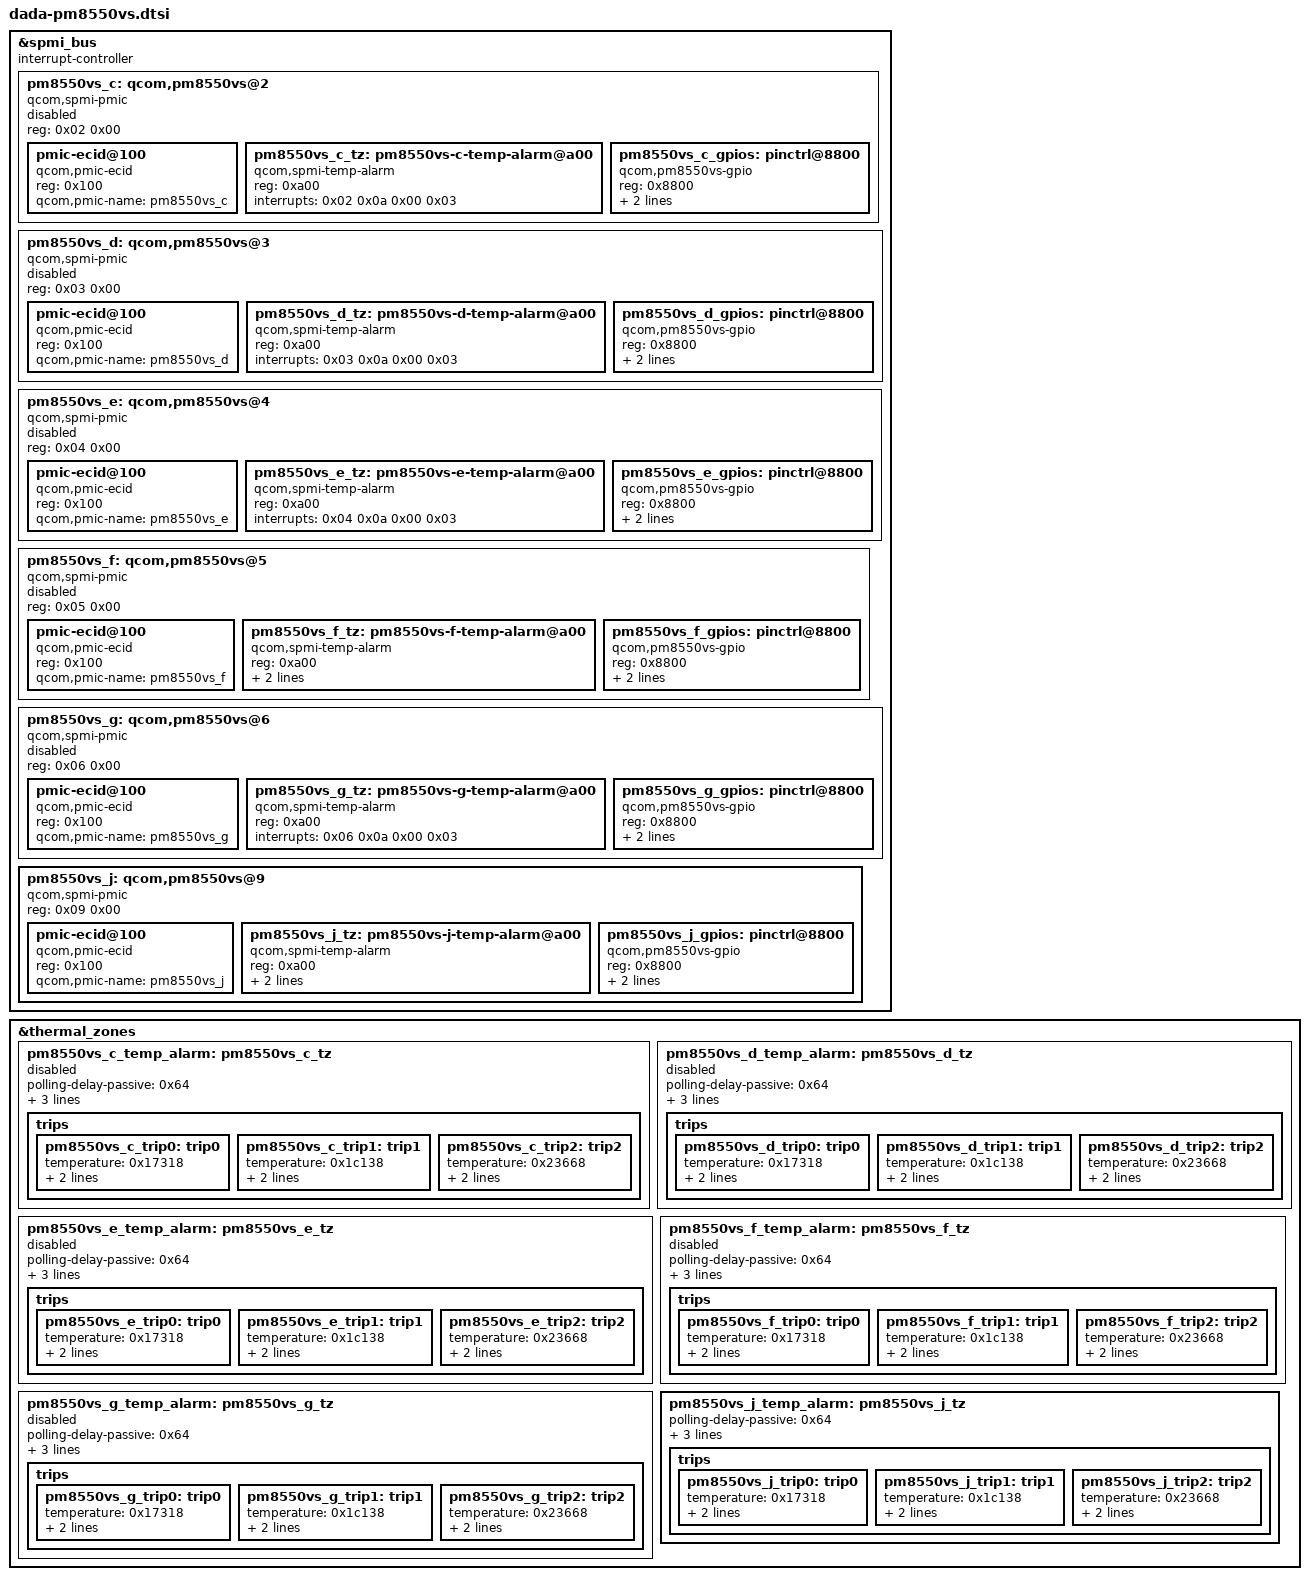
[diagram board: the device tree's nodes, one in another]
// SPDX-License-Identifier: BSD-3-Clause
/*
 * Copyright (c) 2023-2024 Qualcomm Innovation Center, Inc. All rights reserved.
 * Copyright (c) 2025 The LineageOS Project
 */

&spmi_bus {
	#address-cells = <0x02>;
	#size-cells = <0x00>;
	interrupt-controller;
	#interrupt-cells = <0x04>;

	pm8550vs_c: qcom,pm8550vs@2 {
		compatible = "qcom,spmi-pmic";
		reg = <0x02 0x00>;
		#address-cells = <0x01>;
		#size-cells = <0x00>;
		status = "disabled";

		pmic-ecid@100 {
			compatible = "qcom,pmic-ecid";
			reg = <0x100>;
			qcom,pmic-name = "pm8550vs_c";
		};

		pm8550vs_c_tz: pm8550vs-c-temp-alarm@a00 {
			compatible = "qcom,spmi-temp-alarm";
			reg = <0xa00>;
			interrupts = <0x02 0x0a 0x00 0x03>;
			#thermal-sensor-cells = <0x00>;
		};

		pm8550vs_c_gpios: pinctrl@8800 {
			compatible = "qcom,pm8550vs-gpio";
			reg = <0x8800>;
			gpio-controller;
			#gpio-cells = <0x02>;
			interrupt-controller;
			#interrupt-cells = <0x02>;
		};
	};

	pm8550vs_d: qcom,pm8550vs@3 {
		compatible = "qcom,spmi-pmic";
		reg = <0x03 0x00>;
		#address-cells = <0x01>;
		#size-cells = <0x00>;
		status = "disabled";

		pmic-ecid@100 {
			compatible = "qcom,pmic-ecid";
			reg = <0x100>;
			qcom,pmic-name = "pm8550vs_d";
		};

		pm8550vs_d_tz: pm8550vs-d-temp-alarm@a00 {
			compatible = "qcom,spmi-temp-alarm";
			reg = <0xa00>;
			interrupts = <0x03 0x0a 0x00 0x03>;
			#thermal-sensor-cells = <0x00>;
		};

		pm8550vs_d_gpios: pinctrl@8800 {
			compatible = "qcom,pm8550vs-gpio";
			reg = <0x8800>;
			gpio-controller;
			#gpio-cells = <0x02>;
			interrupt-controller;
			#interrupt-cells = <0x02>;
		};
	};

	pm8550vs_e: qcom,pm8550vs@4 {
		compatible = "qcom,spmi-pmic";
		reg = <0x04 0x00>;
		#address-cells = <0x01>;
		#size-cells = <0x00>;
		status = "disabled";

		pmic-ecid@100 {
			compatible = "qcom,pmic-ecid";
			reg = <0x100>;
			qcom,pmic-name = "pm8550vs_e";
		};

		pm8550vs_e_tz: pm8550vs-e-temp-alarm@a00 {
			compatible = "qcom,spmi-temp-alarm";
			reg = <0xa00>;
			interrupts = <0x04 0x0a 0x00 0x03>;
			#thermal-sensor-cells = <0x00>;
		};

		pm8550vs_e_gpios: pinctrl@8800 {
			compatible = "qcom,pm8550vs-gpio";
			reg = <0x8800>;
			gpio-controller;
			#gpio-cells = <0x02>;
			interrupt-controller;
			#interrupt-cells = <0x02>;
		};
	};

	pm8550vs_f: qcom,pm8550vs@5 {
		compatible = "qcom,spmi-pmic";
		reg = <0x05 0x00>;
		#address-cells = <0x01>;
		#size-cells = <0x00>;
		status = "disabled";

		pmic-ecid@100 {
			compatible = "qcom,pmic-ecid";
			reg = <0x100>;
			qcom,pmic-name = "pm8550vs_f";
		};

		pm8550vs_f_tz: pm8550vs-f-temp-alarm@a00 {
			compatible = "qcom,spmi-temp-alarm";
			reg = <0xa00>;
			interrupts = <0x05 0x0a 0x00 0x03>;
			#thermal-sensor-cells = <0x00>;
			io-channels = <&pmk8550_vadc 0x503>;
			io-channel-names = "thermal";
		};

		pm8550vs_f_gpios: pinctrl@8800 {
			compatible = "qcom,pm8550vs-gpio";
			reg = <0x8800>;
			gpio-controller;
			#gpio-cells = <0x02>;
			interrupt-controller;
			#interrupt-cells = <0x02>;
		};
	};

	pm8550vs_g: qcom,pm8550vs@6 {
		compatible = "qcom,spmi-pmic";
		reg = <0x06 0x00>;
		#address-cells = <0x01>;
		#size-cells = <0x00>;
		status = "disabled";

		pmic-ecid@100 {
			compatible = "qcom,pmic-ecid";
			reg = <0x100>;
			qcom,pmic-name = "pm8550vs_g";
		};

		pm8550vs_g_tz: pm8550vs-g-temp-alarm@a00 {
			compatible = "qcom,spmi-temp-alarm";
			reg = <0xa00>;
			interrupts = <0x06 0x0a 0x00 0x03>;
			#thermal-sensor-cells = <0x00>;
		};

		pm8550vs_g_gpios: pinctrl@8800 {
			compatible = "qcom,pm8550vs-gpio";
			reg = <0x8800>;
			gpio-controller;
			#gpio-cells = <0x02>;
			interrupt-controller;
			#interrupt-cells = <0x02>;
		};
	};

	pm8550vs_j: qcom,pm8550vs@9 {
		compatible = "qcom,spmi-pmic";
		reg = <0x09 0x00>;
		#address-cells = <0x01>;
		#size-cells = <0x00>;
		status = "ok";

		pmic-ecid@100 {
			compatible = "qcom,pmic-ecid";
			reg = <0x100>;
			qcom,pmic-name = "pm8550vs_j";
		};

		pm8550vs_j_tz: pm8550vs-j-temp-alarm@a00 {
			compatible = "qcom,spmi-temp-alarm";
			reg = <0xa00>;
			interrupts = <0x09 0x0a 0x00 0x03>;
			#thermal-sensor-cells = <0x00>;
			io-channels = <&pmk8550_vadc 0x903>;
			io-channel-names = "thermal";
		};

		pm8550vs_j_gpios: pinctrl@8800 {
			compatible = "qcom,pm8550vs-gpio";
			reg = <0x8800>;
			gpio-controller;
			#gpio-cells = <0x02>;
			interrupt-controller;
			#interrupt-cells = <0x02>;
		};
	};
};

&thermal_zones {
	pm8550vs_c_temp_alarm: pm8550vs_c_tz {
		polling-delay-passive = <0x64>;
		polling-delay = <0x00>;
		thermal-governor = "step_wise";
		thermal-sensors = <&pm8550vs_c_tz>;
		status = "disabled";

		trips {

			pm8550vs_c_trip0: trip0 {
				temperature = <0x17318>;
				hysteresis = <0x00>;
				type = "passive";
			};

			pm8550vs_c_trip1: trip1 {
				temperature = <0x1c138>;
				hysteresis = <0x00>;
				type = "hot";
			};

			pm8550vs_c_trip2: trip2 {
				temperature = <0x23668>;
				hysteresis = <0x00>;
				type = "critical";
			};
		};
	};

	pm8550vs_d_temp_alarm: pm8550vs_d_tz {
		polling-delay-passive = <0x64>;
		polling-delay = <0x00>;
		thermal-governor = "step_wise";
		thermal-sensors = <&pm8550vs_d_tz>;
		status = "disabled";

		trips {

			pm8550vs_d_trip0: trip0 {
				temperature = <0x17318>;
				hysteresis = <0x00>;
				type = "passive";
			};

			pm8550vs_d_trip1: trip1 {
				temperature = <0x1c138>;
				hysteresis = <0x00>;
				type = "hot";
			};

			pm8550vs_d_trip2: trip2 {
				temperature = <0x23668>;
				hysteresis = <0x00>;
				type = "critical";
			};
		};
	};

	pm8550vs_e_temp_alarm: pm8550vs_e_tz {
		polling-delay-passive = <0x64>;
		polling-delay = <0x00>;
		thermal-governor = "step_wise";
		thermal-sensors = <&pm8550vs_e_tz>;
		status = "disabled";

		trips {

			pm8550vs_e_trip0: trip0 {
				temperature = <0x17318>;
				hysteresis = <0x00>;
				type = "passive";
			};

			pm8550vs_e_trip1: trip1 {
				temperature = <0x1c138>;
				hysteresis = <0x00>;
				type = "hot";
			};

			pm8550vs_e_trip2: trip2 {
				temperature = <0x23668>;
				hysteresis = <0x00>;
				type = "critical";
			};
		};
	};

	pm8550vs_f_temp_alarm: pm8550vs_f_tz {
		polling-delay-passive = <0x64>;
		polling-delay = <0x00>;
		thermal-governor = "step_wise";
		thermal-sensors = <&pm8550vs_f_tz>;
		status = "disabled";

		trips {

			pm8550vs_f_trip0: trip0 {
				temperature = <0x17318>;
				hysteresis = <0x00>;
				type = "passive";
			};

			pm8550vs_f_trip1: trip1 {
				temperature = <0x1c138>;
				hysteresis = <0x00>;
				type = "hot";
			};

			pm8550vs_f_trip2: trip2 {
				temperature = <0x23668>;
				hysteresis = <0x00>;
				type = "critical";
			};
		};
	};

	pm8550vs_g_temp_alarm: pm8550vs_g_tz {
		polling-delay-passive = <0x64>;
		polling-delay = <0x00>;
		thermal-governor = "step_wise";
		thermal-sensors = <&pm8550vs_g_tz>;
		status = "disabled";

		trips {

			pm8550vs_g_trip0: trip0 {
				temperature = <0x17318>;
				hysteresis = <0x00>;
				type = "passive";
			};

			pm8550vs_g_trip1: trip1 {
				temperature = <0x1c138>;
				hysteresis = <0x00>;
				type = "hot";
			};

			pm8550vs_g_trip2: trip2 {
				temperature = <0x23668>;
				hysteresis = <0x00>;
				type = "critical";
			};
		};
	};

	pm8550vs_j_temp_alarm: pm8550vs_j_tz {
		polling-delay-passive = <0x64>;
		polling-delay = <0x00>;
		thermal-governor = "step_wise";
		thermal-sensors = <&pm8550vs_j_tz>;
		status = "ok";

		trips {

			pm8550vs_j_trip0: trip0 {
				temperature = <0x17318>;
				hysteresis = <0x00>;
				type = "passive";
			};

			pm8550vs_j_trip1: trip1 {
				temperature = <0x1c138>;
				hysteresis = <0x00>;
				type = "hot";
			};

			pm8550vs_j_trip2: trip2 {
				temperature = <0x23668>;
				hysteresis = <0x00>;
				type = "critical";
			};
		};
	};
};
